CM_ "IMPORT _honda.dbc";
CM_ "IMPORT _nidec.dbc";
CM_ "IMPORT _comma.dbc";

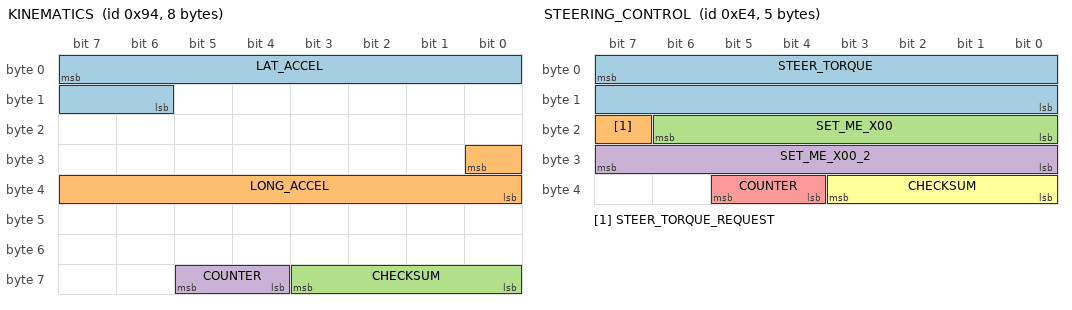
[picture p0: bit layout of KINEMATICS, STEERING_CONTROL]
BO_ 148 KINEMATICS: 8 XXX
 SG_ LAT_ACCEL : 7|10@0+ (0.02,-512) [-20|20] "m/s2" EON
 SG_ LONG_ACCEL : 24|9@0- (-0.02,0) [-20|20] "m/s2" EON
 SG_ CHECKSUM : 59|4@0+ (1,0) [0|3] "" EON
 SG_ COUNTER : 61|2@0+ (1,0) [0|3] "" EON

BO_ 228 STEERING_CONTROL: 5 ADAS
 SG_ STEER_TORQUE : 7|16@0- (1,0) [-3840|3840] "" EPS
 SG_ STEER_TORQUE_REQUEST : 23|1@0+ (1,0) [0|1] "" EPS
 SG_ SET_ME_X00 : 22|7@0+ (1,0) [0|127] "" EPS
 SG_ SET_ME_X00_2 : 31|8@0+ (1,0) [0|0] "" EPS
 SG_ COUNTER : 37|2@0+ (1,0) [0|3] "" EPS
 SG_ CHECKSUM : 35|4@0+ (1,0) [0|15] "" EPS

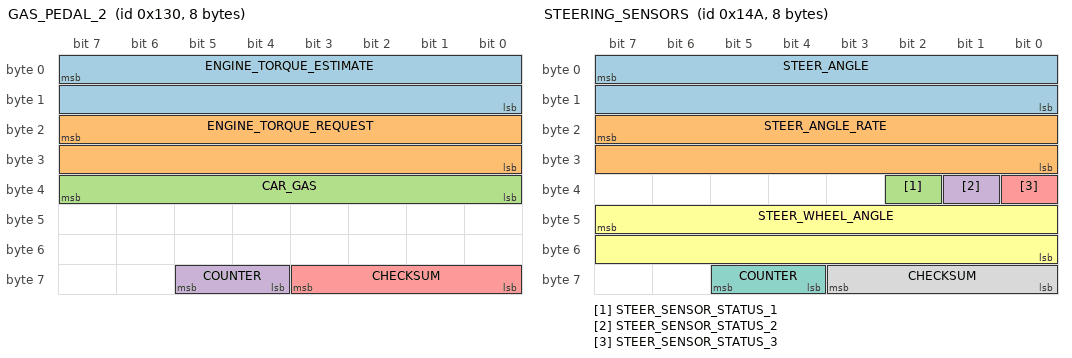
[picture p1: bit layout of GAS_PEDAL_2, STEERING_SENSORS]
BO_ 304 GAS_PEDAL_2: 8 PCM
 SG_ ENGINE_TORQUE_ESTIMATE : 7|16@0- (1,0) [-1000|1000] "Nm" EON
 SG_ ENGINE_TORQUE_REQUEST : 23|16@0- (1,0) [-1000|1000] "Nm" EON
 SG_ CAR_GAS : 39|8@0+ (1,0) [0|255] "" EON
 SG_ COUNTER : 61|2@0+ (1,0) [0|3] "" EON
 SG_ CHECKSUM : 59|4@0+ (1,0) [0|3] "" EON

BO_ 330 STEERING_SENSORS: 8 EPS
 SG_ STEER_ANGLE : 7|16@0- (-0.1,0) [-500|500] "deg" EON
 SG_ STEER_ANGLE_RATE : 23|16@0- (-1,0) [-3000|3000] "deg/s" EON
 SG_ STEER_SENSOR_STATUS_1 : 34|1@0+ (1,0) [0|1] "" EON
 SG_ STEER_SENSOR_STATUS_2 : 33|1@0+ (1,0) [0|1] "" EON
 SG_ STEER_SENSOR_STATUS_3 : 32|1@0+ (1,0) [0|1] "" EON
 SG_ STEER_WHEEL_ANGLE : 47|16@0- (-0.1,0) [-500|500] "deg" EON
 SG_ COUNTER : 61|2@0+ (1,0) [0|3] "" EON
 SG_ CHECKSUM : 59|4@0+ (1,0) [0|3] "" EON

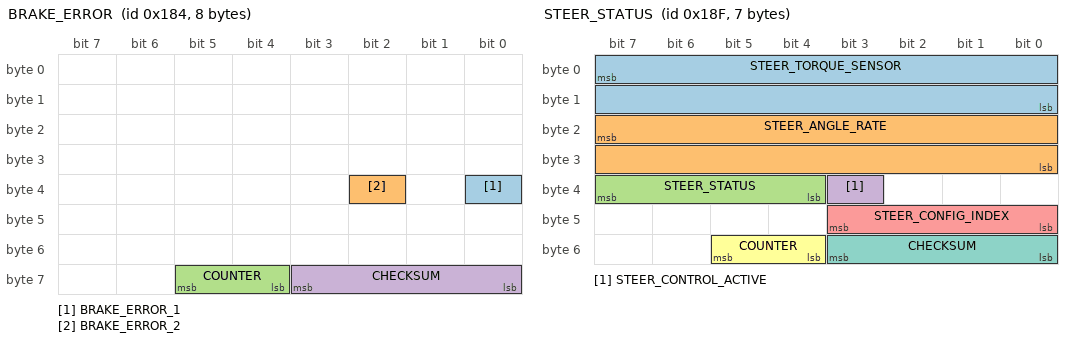
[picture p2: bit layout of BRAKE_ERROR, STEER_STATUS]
BO_ 388 BRAKE_ERROR: 8 XXX
 SG_ BRAKE_ERROR_1 : 32|1@0+ (1,0) [0|1] "" EON
 SG_ BRAKE_ERROR_2 : 34|1@0+ (1,0) [0|1] "" EON
 SG_ COUNTER : 61|2@0+ (1,0) [0|3] "" EON
 SG_ CHECKSUM : 59|4@0+ (1,0) [0|3] "" EON

BO_ 399 STEER_STATUS: 7 EPS
 SG_ STEER_TORQUE_SENSOR : 7|16@0- (-1,0) [-31000|31000] "tbd" EON
 SG_ STEER_ANGLE_RATE : 23|16@0- (-0.1,0) [-31000|31000] "deg/s" EON
 SG_ STEER_STATUS : 39|4@0+ (1,0) [0|15] "" EON
 SG_ STEER_CONTROL_ACTIVE : 35|1@0+ (1,0) [0|1] "" EON
 SG_ STEER_CONFIG_INDEX : 43|4@0+ (1,0) [0|15] "" EON
 SG_ COUNTER : 53|2@0+ (1,0) [0|3] "" EON
 SG_ CHECKSUM : 51|4@0+ (1,0) [0|3] "" EON

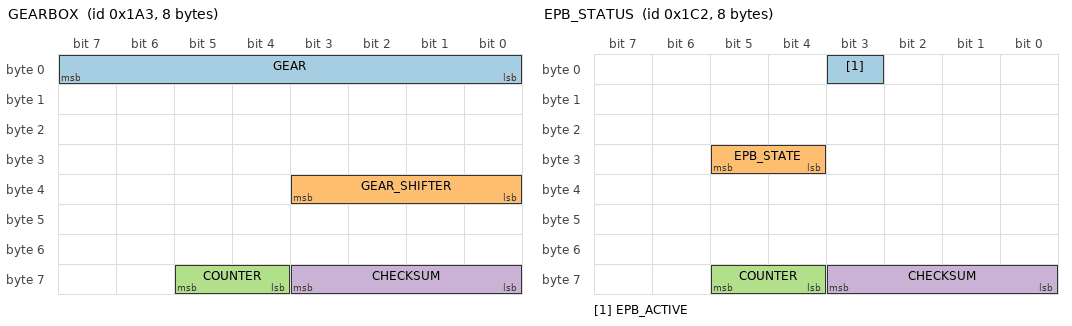
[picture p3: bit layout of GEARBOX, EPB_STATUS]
BO_ 419 GEARBOX: 8 PCM
 SG_ GEAR : 7|8@0+ (1,0) [0|256] "" EON
 SG_ GEAR_SHIFTER : 35|4@0+ (1,0) [0|15] "" EON
 SG_ COUNTER : 61|2@0+ (1,0) [0|3] "" EON
 SG_ CHECKSUM : 59|4@0+ (1,0) [0|3] "" EON

BO_ 450 EPB_STATUS: 8 EPB
 SG_ EPB_ACTIVE : 3|1@0+ (1,0) [0|1] "" EON
 SG_ EPB_STATE : 29|2@0+ (1,0) [0|3] "" EON
 SG_ COUNTER : 61|2@0+ (1,0) [0|3] "" EON
 SG_ CHECKSUM : 59|4@0+ (1,0) [0|3] "" EON

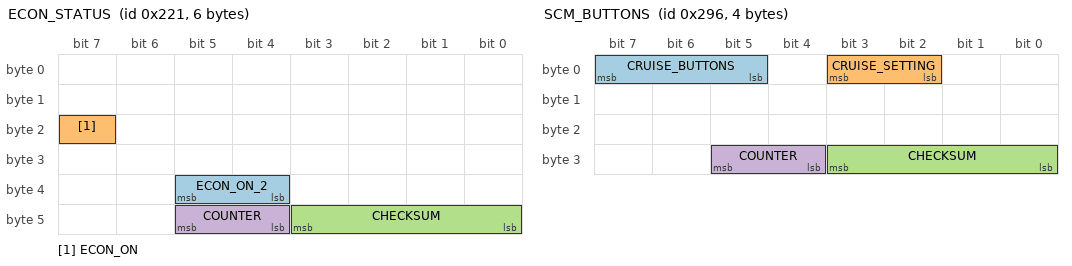
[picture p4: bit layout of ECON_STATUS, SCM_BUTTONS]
BO_ 545 ECON_STATUS: 6 XXX
 SG_ ECON_ON_2 : 37|2@0+ (1,0) [0|3] "" EON
 SG_ ECON_ON : 23|1@0+ (1,0) [0|1] "" EON
 SG_ CHECKSUM : 43|4@0+ (1,0) [0|3] "" EON
 SG_ COUNTER : 45|2@0+ (1,0) [0|3] "" EON

BO_ 662 SCM_BUTTONS: 4 SCM
 SG_ CRUISE_BUTTONS : 7|3@0+ (1,0) [0|7] "" EON
 SG_ CRUISE_SETTING : 3|2@0+ (1,0) [0|3] "" EON
 SG_ CHECKSUM : 27|4@0+ (1,0) [0|3] "" EON
 SG_ COUNTER : 29|2@0+ (1,0) [0|3] "" EON

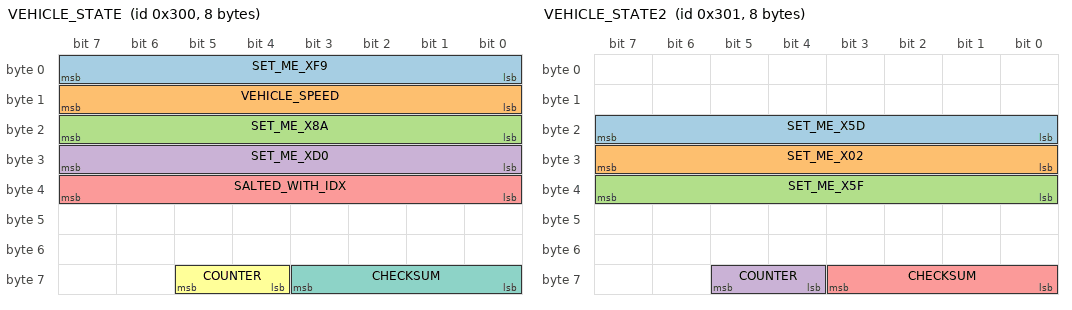
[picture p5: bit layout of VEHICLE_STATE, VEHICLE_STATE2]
BO_ 768 VEHICLE_STATE: 8 ADAS
 SG_ SET_ME_XF9 : 7|8@0+ (1,0) [0|255] "" Vector__XXX
 SG_ VEHICLE_SPEED : 15|8@0+ (1,0) [0|255] "kph" Vector__XXX
 SG_ SET_ME_X8A : 23|8@0+ (1,0) [0|255] "" XXX
 SG_ SET_ME_XD0 : 31|8@0+ (1,0) [0|255] "" XXX
 SG_ SALTED_WITH_IDX : 39|8@0+ (1,0) [0|255] "" XXX
 SG_ COUNTER : 61|2@0+ (1,0) [0|3] "" XXX
 SG_ CHECKSUM : 59|4@0+ (1,0) [0|15] "" XXX

BO_ 769 VEHICLE_STATE2: 8 ADAS
 SG_ SET_ME_X5D : 23|8@0+ (1,0) [0|255] "" XXX
 SG_ SET_ME_X02 : 31|8@0+ (1,0) [0|255] "" XXX
 SG_ SET_ME_X5F : 39|8@0+ (1,0) [0|255] "" XXX
 SG_ COUNTER : 61|2@0+ (1,0) [0|3] "" XXX
 SG_ CHECKSUM : 59|4@0+ (1,0) [0|15] "" XXX

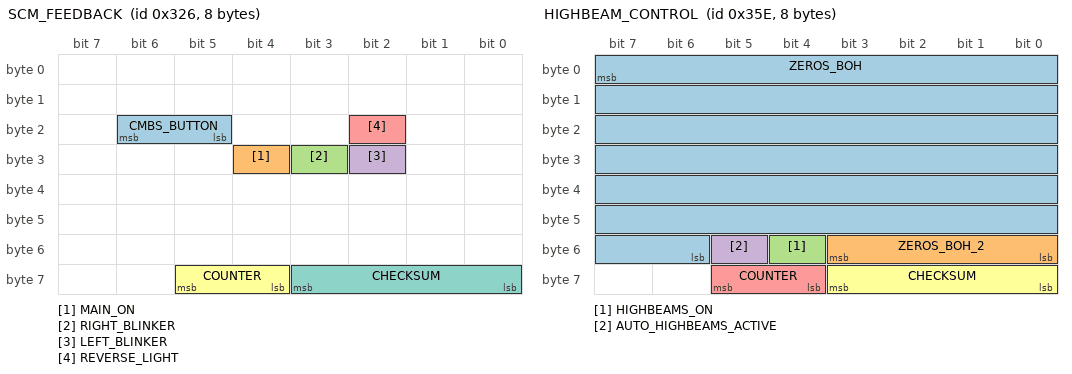
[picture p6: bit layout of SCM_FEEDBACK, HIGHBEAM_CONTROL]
BO_ 806 SCM_FEEDBACK: 8 SCM
 SG_ CMBS_BUTTON : 22|2@0+ (1,0) [0|3] "" EON
 SG_ MAIN_ON : 28|1@0+ (1,0) [0|1] "" EON
 SG_ RIGHT_BLINKER : 27|1@0+ (1,0) [0|1] "" EON
 SG_ LEFT_BLINKER : 26|1@0+ (1,0) [0|1] "" EON
 SG_ REVERSE_LIGHT : 18|1@0+ (1,0) [0|1] "" EON
 SG_ COUNTER : 61|2@0+ (1,0) [0|3] "" EON
 SG_ CHECKSUM : 59|4@0+ (1,0) [0|15] "" EON

BO_ 862 HIGHBEAM_CONTROL: 8 ADAS
 SG_ ZEROS_BOH : 7|50@0+ (1,0) [0|127] "" BDY
 SG_ ZEROS_BOH_2 : 48|4@1+ (1,0) [0|15] "" XXX
 SG_ HIGHBEAMS_ON : 52|1@0+ (1,0) [0|1] "" XXX
 SG_ AUTO_HIGHBEAMS_ACTIVE : 53|1@0+ (1,0) [0|1] "" XXX
 SG_ COUNTER : 61|2@0+ (1,0) [0|3] "" XXX
 SG_ CHECKSUM : 59|4@0+ (1,0) [0|15] "" XXX

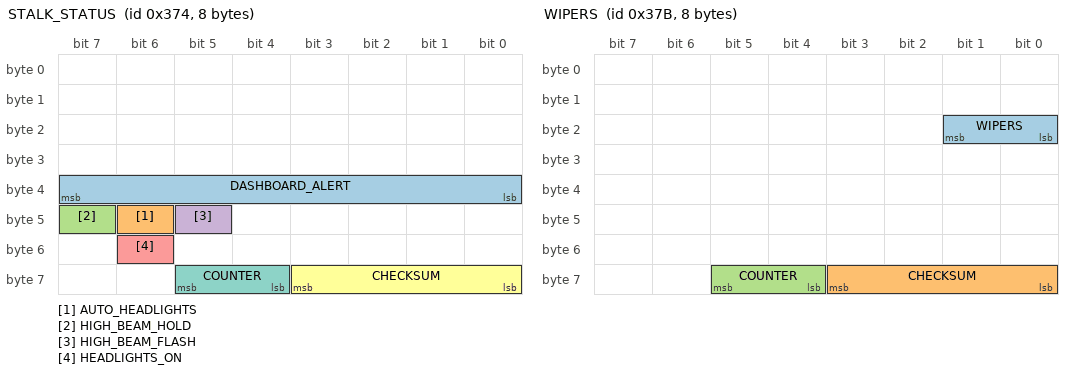
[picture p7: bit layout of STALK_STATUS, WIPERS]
BO_ 884 STALK_STATUS: 8 XXX
 SG_ DASHBOARD_ALERT : 39|8@0+ (1,0) [0|255] "" EON
 SG_ AUTO_HEADLIGHTS : 46|1@0+ (1,0) [0|1] "" EON
 SG_ HIGH_BEAM_HOLD : 47|1@0+ (1,0) [0|1] "" EON
 SG_ HIGH_BEAM_FLASH : 45|1@0+ (1,0) [0|1] "" EON
 SG_ HEADLIGHTS_ON : 54|1@0+ (1,0) [0|1] "" EON
 SG_ CHECKSUM : 59|4@0+ (1,0) [0|15] "" EON
 SG_ COUNTER : 61|2@0+ (1,0) [0|3] "" EON

BO_ 891 WIPERS: 8 XXX
 SG_ WIPERS : 17|2@0+ (1,0) [0|3] "" EON
 SG_ CHECKSUM : 59|4@0+ (1,0) [0|15] "" EON
 SG_ COUNTER : 61|2@0+ (1,0) [0|3] "" EON

BO_ 927 RADAR_HUD: 8 ADAS
 SG_ ZEROS_BOH : 7|17@0+ (1,0) [0|127] "" BDY
 SG_ APPLY_BRAKES_FOR_CANC : 23|1@0+ (1,0) [0|15] "" BDY
 SG_ ZEROS_BOH2 : 31|8@0+ (1,0) [0|127] "" BDY
 SG_ RESUME_INSTRUCTION : 21|1@0+ (1,0) [0|15] "" BDY
 SG_ ACC_ALERTS : 20|5@0+ (1,0) [0|15] "" BDY
 SG_ LEAD_SPEED : 39|9@0+ (1,0) [0|127] "" BDY
 SG_ LEAD_STATE : 46|3@0+ (1,0) [0|127] "" BDY
 SG_ LEAD_DISTANCE : 43|5@0+ (1,0) [0|31] "" BDY
 SG_ ZEROS_BOH3 : 54|7@0+ (1,0) [0|127] "" BDY
 SG_ COUNTER : 61|2@0+ (1,0) [0|3] "" BDY
 SG_ CHECKSUM : 59|4@0+ (1,0) [0|15] "" BDY

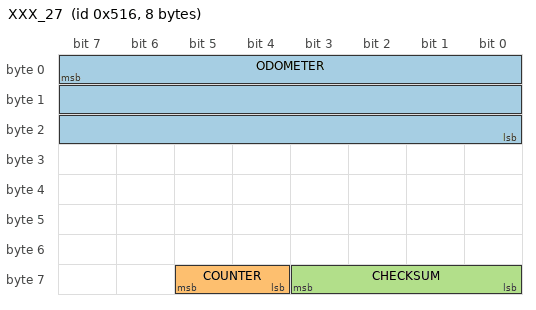
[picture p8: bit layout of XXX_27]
BO_ 1302 XXX_27: 8 XXX
 SG_ ODOMETER : 7|24@0+ (1,0) [0|16777215] "km" EON
 SG_ COUNTER : 61|2@0+ (1,0) [0|3] "" EON
 SG_ CHECKSUM : 59|4@0+ (1,0) [0|15] "" EON

CM_ SG_ 419 GEAR "10 = reverse, 11 = transition";
CM_ SG_ 806 REVERSE_LIGHT "Might be reverse gear selected and not the lights";

VAL_ 399 STEER_STATUS 5 "tmp_fault" 4 "no_torque_alert_2" 2 "no_torque_alert_1" 0 "normal" ;
VAL_ 419 GEAR_SHIFTER 10 "S" 4 "D" 3 "N" 2 "R" 1 "P" ;
VAL_ 450 EPB_STATE 3 "engaged" 2 "disengaging" 1 "engaging" 0 "disengaged" ;
VAL_ 545 ECON_ON_2 0 "off" 3 "on" ;
VAL_ 662 CRUISE_BUTTONS 7 "tbd" 6 "tbd" 5 "tbd" 4 "accel_res" 3 "decel_set" 2 "cancel" 1 "main" 0 "none" ;
VAL_ 662 CRUISE_SETTING 3 "distance_adj" 2 "tbd" 1 "lkas_button" 0 "none" ;
VAL_ 806 CMBS_BUTTON 3 "pressed" 0 "released" ;
VAL_ 884 DASHBOARD_ALERT 0 "none" 51 "acc_problem" 55 "cmbs_problem" 75 "key_not_detected" 79 "fasten_seatbelt" 111 "lkas_problem" 131 "brake_system_problem" 132 "brake_hold_problem" 139 "tbd" 161 "door_open"
VAL_ 891 WIPERS 4 "High" 2 "Low" 0 "Off" ;
VAL_ 927 ACC_ALERTS 29 "esp_active_acc_canceled" 10 "b_pedal_applied" 9 "speed_too_low" 8 "speed_too_high" 7 "p_brake_applied" 6 "gear_no_d" 5 "seatbelt" 4 "too_steep_downhill" 3 "too_steep_uphill" 2 "too_close" 1 "no_vehicle_ahead" ;
